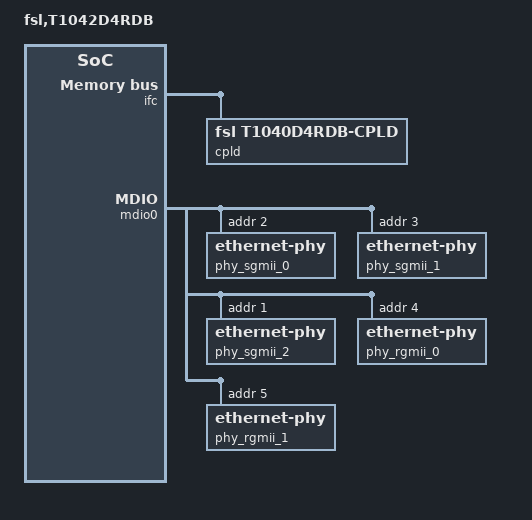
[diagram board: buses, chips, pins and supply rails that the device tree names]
/include/ "t104xsi-pre.dtsi"
/include/ "t104xd4rdb.dtsi"
/ {
	model = "fsl,T1042D4RDB";
	compatible = "fsl,T1042D4RDB";
	#address-cells = <2>;
	#size-cells = <2>;
	interrupt-parent = <&mpic>;
	ifc: localbus@ffe124000 {
		cpld@3,0 {
			compatible = "fsl,t1040d4rdb-cpld",
					"fsl,deepsleep-cpld";
		};
	};
	soc: soc@ffe000000 {
		fman0: fman@400000 {
			ethernet@e0000 {
				phy-handle = <&phy_sgmii_0>;
				phy-connection-type = "sgmii";
			};
			ethernet@e2000 {
				phy-handle = <&phy_sgmii_1>;
				phy-connection-type = "sgmii";
			};
			ethernet@e4000 {
				phy-handle = <&phy_sgmii_2>;
				phy-connection-type = "sgmii";
			};
			ethernet@e6000 {
				phy-handle = <&phy_rgmii_0>;
				phy-connection-type = "rgmii";
			};
			ethernet@e8000 {
				phy-handle = <&phy_rgmii_1>;
				phy-connection-type = "rgmii";
			};
			mdio0: mdio@fc000 {
				phy_sgmii_0: ethernet-phy@2 {
					reg = <0x02>;
				};
				phy_sgmii_1: ethernet-phy@3 {
					reg = <0x03>;
				};
				phy_sgmii_2: ethernet-phy@1 {
					reg = <0x01>;
				};
				phy_rgmii_0: ethernet-phy@4 {
					reg = <0x04>;
				};
				phy_rgmii_1: ethernet-phy@5 {
					reg = <0x05>;
				};
			};
		};
	};
};
#include "t1042si-post.dtsi"
